VERSION ""

NS_ :

BS_:

BU_: WidebandController ECU

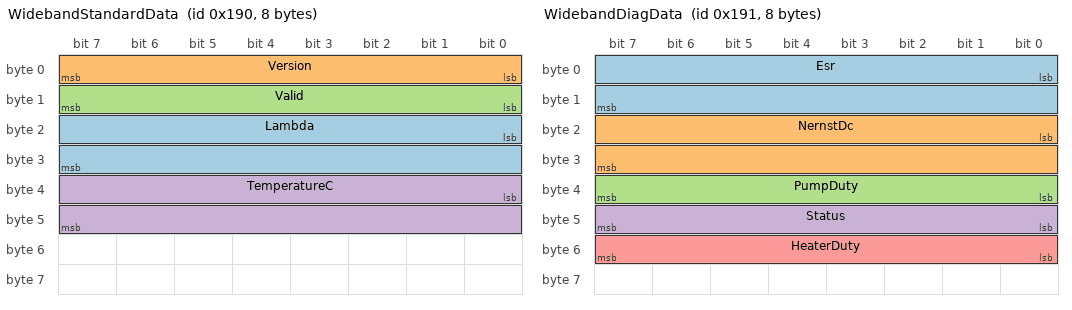
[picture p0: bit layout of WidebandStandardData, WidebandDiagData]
BO_ 400 WidebandStandardData: 8 WidebandController
 SG_ Lambda : 16|16@1+ (0.0001,0) [0.5|2] "lambda"  ECU
 SG_ Version : 0|8@1+ (1,0) [0|0] ""  ECU
 SG_ Valid : 8|8@1+ (1,0) [0|1] ""  ECU
 SG_ TemperatureC : 32|16@1+ (1,0) [0|1000] "deg C"  ECU

BO_ 401 WidebandDiagData: 8 WidebandController
 SG_ Esr : 0|16@1+ (1,0) [0|10000] "ohms"  ECU
 SG_ NernstDc : 16|16@1+ (0.001,0) [0|1.5] "volt"  ECU
 SG_ PumpDuty : 32|8@1+ (0.392157,0) [0|100] "%"  ECU
 SG_ Status : 40|8@1+ (1,0) [0|0] ""  ECU
 SG_ HeaterDuty : 48|8@1+ (0.392157,0) [0|100] "%"  ECU

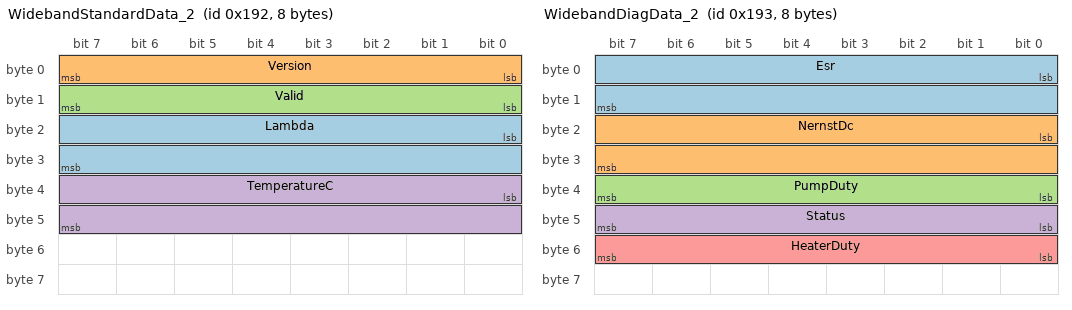
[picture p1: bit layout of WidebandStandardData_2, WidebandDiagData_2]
BO_ 402 WidebandStandardData_2: 8 WidebandController
 SG_ Lambda : 16|16@1+ (0.0001,0) [0.5|2] "lambda"  ECU
 SG_ Version : 0|8@1+ (1,0) [0|0] ""  ECU
 SG_ Valid : 8|8@1+ (1,0) [0|1] ""  ECU
 SG_ TemperatureC : 32|16@1+ (1,0) [0|1000] "deg C"  ECU

BO_ 403 WidebandDiagData_2: 8 WidebandController
 SG_ Esr : 0|16@1+ (1,0) [0|10000] "ohms"  ECU
 SG_ NernstDc : 16|16@1+ (0.001,0) [0|1.5] "volt"  ECU
 SG_ PumpDuty : 32|8@1+ (0.392157,0) [0|100] "%"  ECU
 SG_ Status : 40|8@1+ (1,0) [0|0] ""  ECU
 SG_ HeaterDuty : 48|8@1+ (0.392157,0) [0|100] "%"  ECU

BO_ 2398420992 WidebandControl: 2 ECU
 SG_ BatteryVoltage : 0|8@1+ (0.1,0) [0|25] "volt"  WidebandController
 SG_ HeaterEnable : 8|8@1+ (1,0) [0|1] ""  WidebandController

CM_ BO_ 400 "Offset 0. Increment ID by 2*N for the N-th controller";
CM_ SG_ 400 Version "Currently 0xA0";
CM_ SG_ 400 Valid "Set to 1 when the lambda value is valid";
CM_ BO_ 401 "Offset 0. Increment ID by 2*N for the N-th controller";
CM_ BO_ 402 "Offset 1. Increment ID by 2*N for the N-th controller";
CM_ SG_ 402 Version "Currently 0xA0";
CM_ SG_ 402 Valid "Set to 1 when the lambda value is valid";
CM_ BO_ 403 "Offset 1. Increment ID by 2*N for the N-th controller";

CM_ BO_ 2398420992 "Sent by ECU to control wideband controller";
CM_ SG_ 2398420992 BatteryVoltage "Provide system supply voltage for heater supply voltage compensation";
CM_ SG_ 2398420992 HeaterEnable "Set to 1 to allow sensor heating once engine runs";
